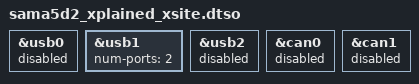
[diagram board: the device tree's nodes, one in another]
// SPDX-License-Identifier: (GPL-2.0+ OR MIT)
/*
 * sama5d2_xplained_i2s0_proto.dtso - Device Tree file for SAMA5D2 Xplained board
 * overlay blob for I2S with PROTO board. The blob uses i2s0 and i2c0.
 *
 * Copyright (C) 2018 Microchip Technology, Inc.
 * Author: Codrin Ciubotariu <codrin.ciubotariu@microchip.com>
 *
 */
/dts-v1/;
/plugin/;

#include "sama5d2-pinfunc.h"
#include "dt-bindings/pinctrl/at91.h"
#include <dt-bindings/gpio/gpio.h>

&usb0 {
	status = "disabled";
};

&usb1 {
	num-ports = <2>;
	status = "okay";
};

&usb2 {
	status = "disabled";
};

&can0 {
	status = "disabled";
};

&can1 {
	status = "disabled";
};
